AUTOSAR XML (schema 4-0-3)
package /ComponentTypes
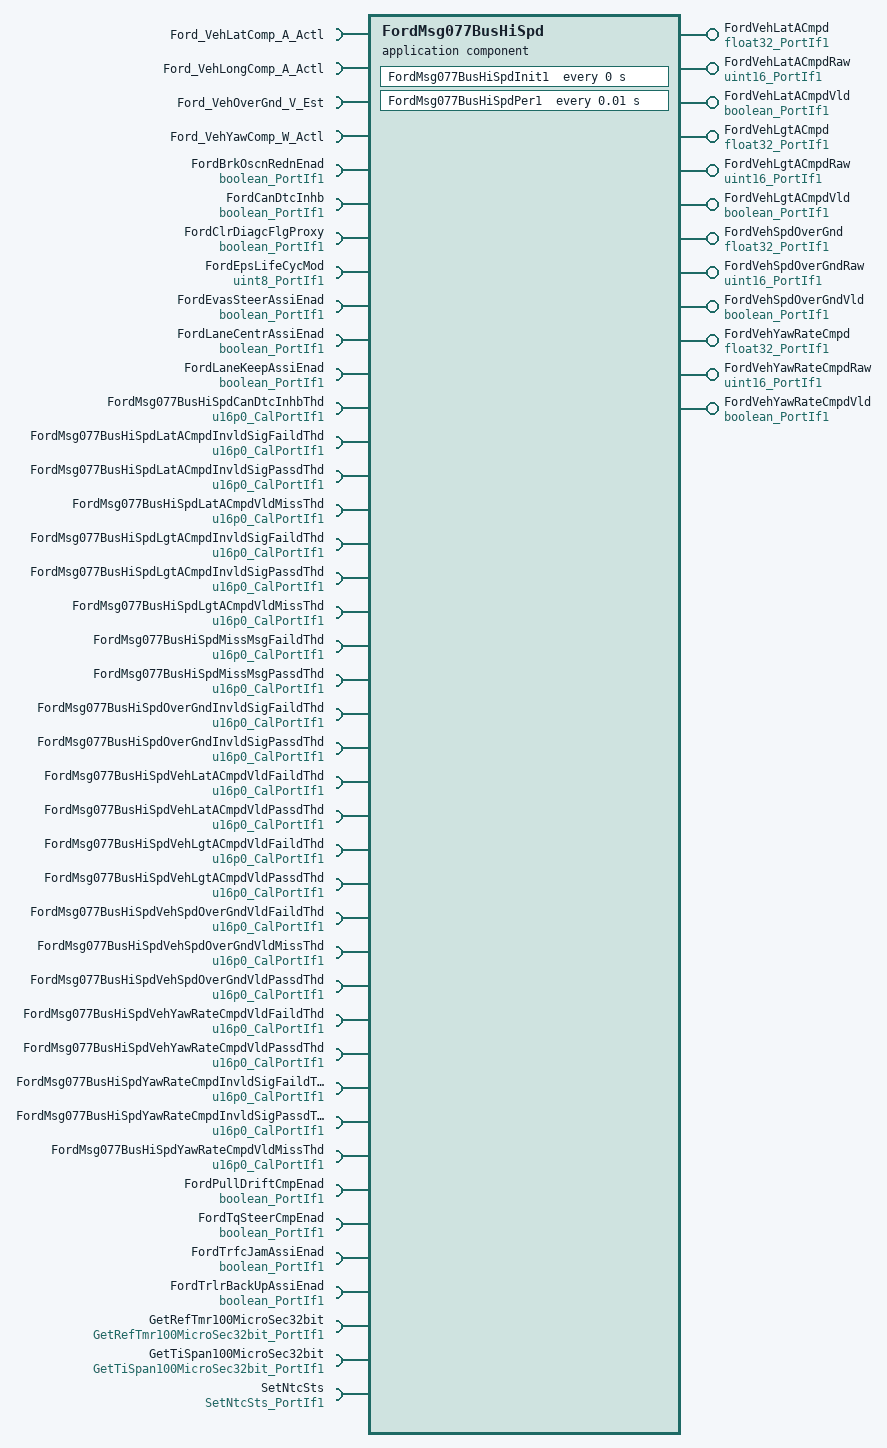
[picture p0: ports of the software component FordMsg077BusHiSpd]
  application sw component type FordMsg077BusHiSpd
    12 x provide port:
      FordVehLatACmpd: nonqueued-sender-com-spec{data-element=Val, init-value=17.835}, provided-interface=float32_PortIf1
      FordVehLatACmpdRaw: nonqueued-sender-com-spec{data-element=Val, init-value=1022}, provided-interface=uint16_PortIf1
      FordVehLatACmpdVld: nonqueued-sender-com-spec{data-element=Logl, init-value=0}, provided-interface=boolean_PortIf1
      FordVehLgtACmpd: nonqueued-sender-com-spec{data-element=Val, init-value=17.835}, provided-interface=float32_PortIf1
      FordVehLgtACmpdRaw: nonqueued-sender-com-spec{data-element=Val, init-value=1022}, provided-interface=uint16_PortIf1
      FordVehLgtACmpdVld: nonqueued-sender-com-spec{data-element=Logl, init-value=0}, provided-interface=boolean_PortIf1
      FordVehSpdOverGnd: nonqueued-sender-com-spec{data-element=Val, init-value=0}, provided-interface=float32_PortIf1
      FordVehSpdOverGndRaw: nonqueued-sender-com-spec{data-element=Val, init-value=0}, provided-interface=uint16_PortIf1
      FordVehSpdOverGndVld: nonqueued-sender-com-spec{data-element=Logl, init-value=0}, provided-interface=boolean_PortIf1
      FordVehYawRateCmpd: nonqueued-sender-com-spec{data-element=Val, init-value=74.92659}, provided-interface=float32_PortIf1
      FordVehYawRateCmpdRaw: nonqueued-sender-com-spec{data-element=Val, init-value=4094}, provided-interface=uint16_PortIf1
      FordVehYawRateCmpdVld: nonqueued-sender-com-spec{data-element=Logl, init-value=0}, provided-interface=boolean_PortIf1
    41 x require port:
      Ford_VehLatComp_A_Actl: nonqueued-receiver-com-spec{data-element=Ford_VehLatComp_A_Actl, filter=data-filter-type=ALWAYS, init-value=1022}, required-interface=Ford_VehLatComp_A_Actl
      Ford_VehLongComp_A_Actl: nonqueued-receiver-com-spec{data-element=Ford_VehLongComp_A_Actl, filter=data-filter-type=ALWAYS, init-value=1022}, required-interface=Ford_VehLongComp_A_Actl
      Ford_VehOverGnd_V_Est: nonqueued-receiver-com-spec{data-element=Ford_VehOverGnd_V_Est, filter=data-filter-type=ALWAYS, init-value=0}, required-interface=Ford_VehOverGnd_V_Est
      Ford_VehYawComp_W_Actl: nonqueued-receiver-com-spec{data-element=Ford_VehYawComp_W_Actl, filter=data-filter-type=ALWAYS, init-value=4094}, required-interface=Ford_VehYawComp_W_Actl
      FordBrkOscnRednEnad: nonqueued-receiver-com-spec{data-element=Logl, filter=data-filter-type=ALWAYS, init-value=0}, required-interface=boolean_PortIf1
      FordCanDtcInhb: nonqueued-receiver-com-spec{data-element=Logl, filter=data-filter-type=ALWAYS, init-value=1}, required-interface=boolean_PortIf1
      FordClrDiagcFlgProxy: nonqueued-receiver-com-spec{data-element=Logl, filter=data-filter-type=ALWAYS, init-value=0}, required-interface=boolean_PortIf1
      FordEpsLifeCycMod: nonqueued-receiver-com-spec{data-element=Val, filter=data-filter-type=ALWAYS, init-value=0}, required-interface=uint8_PortIf1
      FordEvasSteerAssiEnad: nonqueued-receiver-com-spec{data-element=Logl, filter=data-filter-type=ALWAYS, init-value=0}, required-interface=boolean_PortIf1
      FordLaneCentrAssiEnad: nonqueued-receiver-com-spec{data-element=Logl, filter=data-filter-type=ALWAYS, init-value=0}, required-interface=boolean_PortIf1
      FordLaneKeepAssiEnad: nonqueued-receiver-com-spec{data-element=Logl, filter=data-filter-type=ALWAYS, init-value=0}, required-interface=boolean_PortIf1
      FordMsg077BusHiSpdCanDtcInhbThd: parameter-require-com-spec{init-value=2000, parameter=Val}, required-interface=u16p0_CalPortIf1
      FordMsg077BusHiSpdLatACmpdInvldSigFaildThd: parameter-require-com-spec{init-value=0, parameter=Val}, required-interface=u16p0_CalPortIf1
      FordMsg077BusHiSpdLatACmpdInvldSigPassdThd: parameter-require-com-spec{init-value=0, parameter=Val}, required-interface=u16p0_CalPortIf1
      FordMsg077BusHiSpdLatACmpdVldMissThd: parameter-require-com-spec{init-value=100, parameter=Val}, required-interface=u16p0_CalPortIf1
      FordMsg077BusHiSpdLgtACmpdInvldSigFaildThd: parameter-require-com-spec{init-value=0, parameter=Val}, required-interface=u16p0_CalPortIf1
      FordMsg077BusHiSpdLgtACmpdInvldSigPassdThd: parameter-require-com-spec{init-value=0, parameter=Val}, required-interface=u16p0_CalPortIf1
      FordMsg077BusHiSpdLgtACmpdVldMissThd: parameter-require-com-spec{init-value=100, parameter=Val}, required-interface=u16p0_CalPortIf1
      FordMsg077BusHiSpdMissMsgFaildThd: parameter-require-com-spec{init-value=100, parameter=Val}, required-interface=u16p0_CalPortIf1
      FordMsg077BusHiSpdMissMsgPassdThd: parameter-require-com-spec{init-value=0, parameter=Val}, required-interface=u16p0_CalPortIf1
      FordMsg077BusHiSpdOverGndInvldSigFaildThd: parameter-require-com-spec{init-value=0, parameter=Val}, required-interface=u16p0_CalPortIf1
      FordMsg077BusHiSpdOverGndInvldSigPassdThd: parameter-require-com-spec{init-value=0, parameter=Val}, required-interface=u16p0_CalPortIf1
      FordMsg077BusHiSpdVehLatACmpdVldFaildThd: parameter-require-com-spec{init-value=0, parameter=Val}, required-interface=u16p0_CalPortIf1
      FordMsg077BusHiSpdVehLatACmpdVldPassdThd: parameter-require-com-spec{init-value=5000, parameter=Val}, required-interface=u16p0_CalPortIf1
      FordMsg077BusHiSpdVehLgtACmpdVldFaildThd: parameter-require-com-spec{init-value=0, parameter=Val}, required-interface=u16p0_CalPortIf1
      FordMsg077BusHiSpdVehLgtACmpdVldPassdThd: parameter-require-com-spec{init-value=500, parameter=Val}, required-interface=u16p0_CalPortIf1
      FordMsg077BusHiSpdVehSpdOverGndVldFaildThd: parameter-require-com-spec{init-value=0, parameter=Val}, required-interface=u16p0_CalPortIf1
      FordMsg077BusHiSpdVehSpdOverGndVldMissThd: parameter-require-com-spec{init-value=100, parameter=Val}, required-interface=u16p0_CalPortIf1
      FordMsg077BusHiSpdVehSpdOverGndVldPassdThd: parameter-require-com-spec{init-value=0, parameter=Val}, required-interface=u16p0_CalPortIf1
      FordMsg077BusHiSpdVehYawRateCmpdVldFaildThd: parameter-require-com-spec{init-value=0, parameter=Val}, required-interface=u16p0_CalPortIf1
      FordMsg077BusHiSpdVehYawRateCmpdVldPassdThd: parameter-require-com-spec{init-value=5000, parameter=Val}, required-interface=u16p0_CalPortIf1
      FordMsg077BusHiSpdYawRateCmpdInvldSigFaildThd: parameter-require-com-spec{init-value=0, parameter=Val}, required-interface=u16p0_CalPortIf1
      FordMsg077BusHiSpdYawRateCmpdInvldSigPassdThd: parameter-require-com-spec{init-value=0, parameter=Val}, required-interface=u16p0_CalPortIf1
      FordMsg077BusHiSpdYawRateCmpdVldMissThd: parameter-require-com-spec{init-value=100, parameter=Val}, required-interface=u16p0_CalPortIf1
      FordPullDriftCmpEnad: nonqueued-receiver-com-spec{data-element=Logl, filter=data-filter-type=ALWAYS, init-value=0}, required-interface=boolean_PortIf1
      FordTqSteerCmpEnad: nonqueued-receiver-com-spec{data-element=Logl, filter=data-filter-type=ALWAYS, init-value=0}, required-interface=boolean_PortIf1
      FordTrfcJamAssiEnad: nonqueued-receiver-com-spec{data-element=Logl, filter=data-filter-type=ALWAYS, init-value=0}, required-interface=boolean_PortIf1
      FordTrlrBackUpAssiEnad: nonqueued-receiver-com-spec{data-element=Logl, filter=data-filter-type=ALWAYS, init-value=0}, required-interface=boolean_PortIf1
      GetRefTmr100MicroSec32bit: client-com-spec=Oper, required-interface=GetRefTmr100MicroSec32bit_PortIf1
      GetTiSpan100MicroSec32bit: client-com-spec=Oper, required-interface=GetTiSpan100MicroSec32bit_PortIf1
      SetNtcSts: client-com-spec=Oper, required-interface=SetNtcSts_PortIf1
    behavior FordMsg077BusHiSpd_InternalBehavior
      ar-typed-per-instance-memorys:
        38 x data, all with sw-calibration-access=READ-ONLY:
          CanDtcInhbRefTi: type=uint32
          DiagcClrProxyFlgPrev: type=boolean
          FirstTranVldFlg: type=boolean
          FordVehLatACmpdInvldFaildRefTi: type=uint32
          FordVehLatACmpdInvldPassdRefTi: type=uint32
          FordVehLatACmpdPrev: type=float32
          FordVehLatACmpdRawPrev: type=uint16
          FordVehLatACmpdVldFaildRefTi: type=uint32
          FordVehLatACmpdVldMissRefTi: type=uint32
          FordVehLatACmpdVldPassdRefTi: type=uint32
          FordVehLatACmpdVldPrev: type=boolean
          FordVehLgtACmpdInvldFaildRefTi: type=uint32
          FordVehLgtACmpdInvldPassdRefTi: type=uint32
          FordVehLgtACmpdPrev: type=float32
          FordVehLgtACmpdRawPrev: type=uint16
          FordVehLgtACmpdVldFaildRefTi: type=uint32
          FordVehLgtACmpdVldMissRefTi: type=uint32
          FordVehLgtACmpdVldPassdRefTi: type=uint32
          FordVehLgtACmpdVldPrev: type=boolean
          FordVehMsg77Miss: type=boolean
          FordVehSpdOverGndInvldFaildRefTi: type=uint32
          FordVehSpdOverGndInvldPassdRefTi: type=uint32
          FordVehSpdOverGndPrev: type=float32
          FordVehSpdOverGndRawPrev: type=uint16
          FordVehSpdOverGndVldFaildRefTi: type=uint32
          FordVehSpdOverGndVldMissRefTi: type=uint32
          FordVehSpdOverGndVldPassdRefTi: type=uint32
          FordVehSpdOverGndVldPrev: type=boolean
          FordVehYawRateCmpdInvldFaildRefTi: type=uint32
          FordVehYawRateCmpdInvldPassdRefTi: type=uint32
          FordVehYawRateCmpdPrev: type=float32
          FordVehYawRateCmpdRawPrev: type=uint16
          FordVehYawRateCmpdVldFaildRefTi: type=uint32
          FordVehYawRateCmpdVldMissRefTi: type=uint32
          FordVehYawRateCmpdVldPassdRefTi: type=uint32
          FordVehYawRateCmpdVldPrev: type=boolean
          MissMsgFaildRefTi: type=uint32
          MissMsgPassdRefTi: type=uint32
      timing event FordMsg077BusHiSpd_InitEvent: start-on-event=FordMsg077BusHiSpdInit1, period=0
      timing event TMT_FordMsg077BusHiSpdPer1: start-on-event=FordMsg077BusHiSpdPer1, period=0.01
      port-api-options:
        enable-take-address=false, indirect-api=false, port=Ford_VehLatComp_A_Actl
        enable-take-address=false, indirect-api=false, port=Ford_VehLongComp_A_Actl
        enable-take-address=false, indirect-api=false, port=Ford_VehOverGnd_V_Est
        enable-take-address=false, indirect-api=false, port=Ford_VehYawComp_W_Actl
        enable-take-address=false, indirect-api=false, port=FordBrkOscnRednEnad
        enable-take-address=false, indirect-api=false, port=FordCanDtcInhb
        enable-take-address=false, indirect-api=false, port=FordClrDiagcFlgProxy
        enable-take-address=false, indirect-api=false, port=FordEpsLifeCycMod
        enable-take-address=false, indirect-api=false, port=FordEvasSteerAssiEnad
        enable-take-address=false, indirect-api=false, port=FordLaneCentrAssiEnad
        enable-take-address=false, indirect-api=false, port=FordLaneKeepAssiEnad
        enable-take-address=false, indirect-api=false, port=FordMsg077BusHiSpdCanDtcInhbThd
        enable-take-address=false, indirect-api=false, port=FordMsg077BusHiSpdLatACmpdInvldSigFaildThd
        enable-take-address=false, indirect-api=false, port=FordMsg077BusHiSpdLatACmpdInvldSigPassdThd
        enable-take-address=false, indirect-api=false, port=FordMsg077BusHiSpdLatACmpdVldMissThd
        enable-take-address=false, indirect-api=false, port=FordMsg077BusHiSpdLgtACmpdInvldSigFaildThd
        enable-take-address=false, indirect-api=false, port=FordMsg077BusHiSpdLgtACmpdInvldSigPassdThd
        enable-take-address=false, indirect-api=false, port=FordMsg077BusHiSpdLgtACmpdVldMissThd
        enable-take-address=false, indirect-api=false, port=FordMsg077BusHiSpdMissMsgFaildThd
        enable-take-address=false, indirect-api=false, port=FordMsg077BusHiSpdMissMsgPassdThd
        enable-take-address=false, indirect-api=false, port=FordMsg077BusHiSpdOverGndInvldSigFaildThd
        enable-take-address=false, indirect-api=false, port=FordMsg077BusHiSpdOverGndInvldSigPassdThd
        enable-take-address=false, indirect-api=false, port=FordMsg077BusHiSpdVehLatACmpdVldFaildThd
        enable-take-address=false, indirect-api=false, port=FordMsg077BusHiSpdVehLatACmpdVldPassdThd
        enable-take-address=false, indirect-api=false, port=FordMsg077BusHiSpdVehLgtACmpdVldFaildThd
        enable-take-address=false, indirect-api=false, port=FordMsg077BusHiSpdVehLgtACmpdVldPassdThd
        enable-take-address=false, indirect-api=false, port=FordMsg077BusHiSpdVehSpdOverGndVldFaildThd
        enable-take-address=false, indirect-api=false, port=FordMsg077BusHiSpdVehSpdOverGndVldMissThd
        enable-take-address=false, indirect-api=false, port=FordMsg077BusHiSpdVehSpdOverGndVldPassdThd
        enable-take-address=false, indirect-api=false, port=FordMsg077BusHiSpdVehYawRateCmpdVldFaildThd
        enable-take-address=false, indirect-api=false, port=FordMsg077BusHiSpdVehYawRateCmpdVldPassdThd
        enable-take-address=false, indirect-api=false, port=FordMsg077BusHiSpdYawRateCmpdInvldSigFaildThd
        enable-take-address=false, indirect-api=false, port=FordMsg077BusHiSpdYawRateCmpdInvldSigPassdThd
        enable-take-address=false, indirect-api=false, port=FordMsg077BusHiSpdYawRateCmpdVldMissThd
        enable-take-address=false, indirect-api=false, port=FordPullDriftCmpEnad
        enable-take-address=false, indirect-api=false, port=FordTqSteerCmpEnad
        enable-take-address=false, indirect-api=false, port=FordTrfcJamAssiEnad
        enable-take-address=false, indirect-api=false, port=FordTrlrBackUpAssiEnad
        enable-take-address=false, indirect-api=false, port=FordVehLatACmpd
        enable-take-address=false, indirect-api=false, port=FordVehLatACmpdRaw
        enable-take-address=false, indirect-api=false, port=FordVehLatACmpdVld
        enable-take-address=false, indirect-api=false, port=FordVehLgtACmpd
        enable-take-address=false, indirect-api=false, port=FordVehLgtACmpdRaw
        enable-take-address=false, indirect-api=false, port=FordVehLgtACmpdVld
        enable-take-address=false, indirect-api=false, port=FordVehSpdOverGnd
        enable-take-address=false, indirect-api=false, port=FordVehSpdOverGndRaw
        enable-take-address=false, indirect-api=false, port=FordVehSpdOverGndVld
        enable-take-address=false, indirect-api=false, port=FordVehYawRateCmpd
        enable-take-address=false, indirect-api=false, port=FordVehYawRateCmpdRaw
        enable-take-address=false, indirect-api=false, port=FordVehYawRateCmpdVld
        enable-take-address=false, indirect-api=false, port=GetRefTmr100MicroSec32bit
        enable-take-address=false, indirect-api=false, port=GetTiSpan100MicroSec32bit
        enable-take-address=false, indirect-api=false, port=SetNtcSts
      runnable FordMsg077BusHiSpdInit1
        sync call SC_GetRefTmr100MicroSec32bit_Oper: operation=GetRefTmr100MicroSec32bit.Oper, timeout=0
      runnable FordMsg077BusHiSpdPer1: minimum-start-interval=0.01
        data-receive-point-by-arguments:
          15 x access:
            REC_Ford_VehLatComp_A_Actl_Ford_VehLatComp_A_Actl: accessed-variable=Ford_VehLatComp_A_Actl.Ford_VehLatComp_A_Actl
            REC_Ford_VehLongComp_A_Actl_Ford_VehLongComp_A_Actl: accessed-variable=Ford_VehLongComp_A_Actl.Ford_VehLongComp_A_Actl
            REC_Ford_VehOverGnd_V_Est_Ford_VehOverGnd_V_Est: accessed-variable=Ford_VehOverGnd_V_Est.Ford_VehOverGnd_V_Est
            REC_Ford_VehYawComp_W_Actl_Ford_VehYawComp_W_Actl: accessed-variable=Ford_VehYawComp_W_Actl.Ford_VehYawComp_W_Actl
            REC_FordBrkOscnRednEnad_Logl: accessed-variable=FordBrkOscnRednEnad.Logl
            REC_FordCanDtcInhb_Logl: accessed-variable=FordCanDtcInhb.Logl
            REC_FordClrDiagcFlgProxy_Logl: accessed-variable=FordClrDiagcFlgProxy.Logl
            REC_FordEpsLifeCycMod_Val: accessed-variable=FordEpsLifeCycMod.Val
            REC_FordEvasSteerAssiEnad_Logl: accessed-variable=FordEvasSteerAssiEnad.Logl
            REC_FordLaneCentrAssiEnad_Logl: accessed-variable=FordLaneCentrAssiEnad.Logl
            REC_FordLaneKeepAssiEnad_Logl: accessed-variable=FordLaneKeepAssiEnad.Logl
            REC_FordPullDriftCmpEnad_Logl: accessed-variable=FordPullDriftCmpEnad.Logl
            REC_FordTqSteerCmpEnad_Logl: accessed-variable=FordTqSteerCmpEnad.Logl
            REC_FordTrfcJamAssiEnad_Logl: accessed-variable=FordTrfcJamAssiEnad.Logl
            REC_FordTrlrBackUpAssiEnad_Logl: accessed-variable=FordTrlrBackUpAssiEnad.Logl
        data-send-points:
          12 x access:
            SEND_FordVehLatACmpd_Val: accessed-variable=FordVehLatACmpd.Val
            SEND_FordVehLatACmpdRaw_Val: accessed-variable=FordVehLatACmpdRaw.Val
            SEND_FordVehLatACmpdVld_Logl: accessed-variable=FordVehLatACmpdVld.Logl
            SEND_FordVehLgtACmpd_Val: accessed-variable=FordVehLgtACmpd.Val
            SEND_FordVehLgtACmpdRaw_Val: accessed-variable=FordVehLgtACmpdRaw.Val
            SEND_FordVehLgtACmpdVld_Logl: accessed-variable=FordVehLgtACmpdVld.Logl
            SEND_FordVehSpdOverGnd_Val: accessed-variable=FordVehSpdOverGnd.Val
            SEND_FordVehSpdOverGndRaw_Val: accessed-variable=FordVehSpdOverGndRaw.Val
            SEND_FordVehSpdOverGndVld_Logl: accessed-variable=FordVehSpdOverGndVld.Logl
            SEND_FordVehYawRateCmpd_Val: accessed-variable=FordVehYawRateCmpd.Val
            SEND_FordVehYawRateCmpdRaw_Val: accessed-variable=FordVehYawRateCmpdRaw.Val
            SEND_FordVehYawRateCmpdVld_Logl: accessed-variable=FordVehYawRateCmpdVld.Logl
        sync call SC_GetRefTmr100MicroSec32bit_Oper: operation=GetRefTmr100MicroSec32bit.Oper, timeout=0
        sync call SC_GetTiSpan100MicroSec32bit_Oper: operation=GetTiSpan100MicroSec32bit.Oper, timeout=0
        sync call SC_SetNtcSts_Oper: operation=SetNtcSts.Oper, timeout=0
  swc implementation FordMsg077BusHiSpd_Implementation: behavior=FordMsg077BusHiSpd_InternalBehavior
    code-descriptors:
      code Default: artifact-descriptors=autosar-engineering-object={short-label=Default, category=SWSRC}
